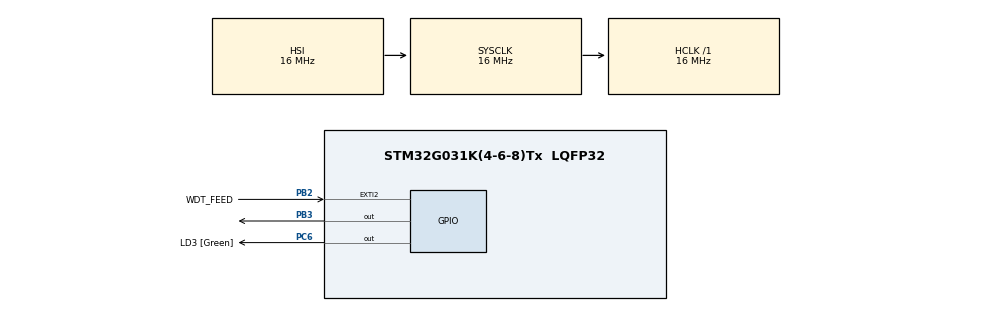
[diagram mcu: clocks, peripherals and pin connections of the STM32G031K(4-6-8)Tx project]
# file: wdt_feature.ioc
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Mcu.Family=STM32G0
Mcu.Name=STM32G031K(4-6-8)Tx
Mcu.Package=LQFP32
NVIC.EXTI2_3_IRQn=true\:0\:0\:false\:false\:true\:true\:true\:true
PA13.GPIO_Label=T_JTMS
PA13.Mode=Serial_Wire
PA13.Signal=SYS_SWDIO
PA14-BOOT0.GPIO_Label=T_JTCK
PA14-BOOT0.Mode=Serial_Wire
PA14-BOOT0.Signal=SYS_SWCLK
PA2.GPIO_Label=T_VCP_TX
PA2.GPIO_PuPd=GPIO_PULLUP
PA2.Signal=USART2_TX
PA3.GPIO_Label=T_VCP_RX
PA3.GPIO_PuPd=GPIO_PULLUP
PA3.Signal=USART2_RX
PB2.GPIO_Label=WDT_FEED
PB2.Signal=GPXTI2
PB3.Signal=GPIO_Output
PC14-OSC32_IN\ (PC14).Mode=LSE-External-Oscillator
PC14-OSC32_IN\ (PC14).Signal=RCC_OSC32_IN
PC15-OSC32_OUT\ (PC15).Mode=LSE-External-Oscillator
PC15-OSC32_OUT\ (PC15).Signal=RCC_OSC32_OUT
PC6.GPIO_Label=LD3 [Green]
PC6.Signal=GPIO_Output
ProjectManager.HeapSize=0x200
ProjectManager.StackSize=0x400
ProjectManager.TargetToolchain=STM32CubeIDE
RCC.AHBFreq_Value=16000000
RCC.CortexFreq_Value=16000000
RCC.EXTERNAL_CLOCK_VALUE=12288000
RCC.HCLKFreq_Value=16000000
RCC.HSE_VALUE=8000000
RCC.HSI_VALUE=16000000
RCC.SYSCLKFreq_VALUE=16000000
RCC.VCOOutputFreq_Value=128000000
board=NUCLEO-G031K8

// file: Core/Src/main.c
/* USER CODE BEGIN Header */
/**
  ******************************************************************************
  * @file           : main.c
  * @brief          : Main program body
  ******************************************************************************
  * @attention
  *
  * Copyright (c) 2022 STMicroelectronics.
  * All rights reserved.
  *
  * This software is licensed under terms that can be found in the LICENSE file
  * in the root directory of this software component.
  * If no LICENSE file comes with this software, it is provided AS-IS.
  *
  ******************************************************************************
  */
/* USER CODE END Header */
#include "main.h"

/* USER CODE BEGIN PV */
uint8_t flag = 0;
/* USER CODE END PV */

void SystemClock_Config(void);
static void MX_GPIO_Init(void);
/* USER CODE BEGIN PFP */
void HAL_GPIO_EXTI_Rising_Callback(uint16_t GPIO_Pin);
/* USER CODE END PFP */

int main(void)
{

  /* MCU Configuration--------------------------------------------------------*/

  /* Reset of all peripherals, Initializes the Flash interface and the Systick. */
  HAL_Init();

  /* Configure the system clock */
  SystemClock_Config();

  /* Initialize all configured peripherals */
  MX_GPIO_Init();

  /* Infinite loop */
  /* USER CODE BEGIN WHILE */
  while (1)
  {
	  if (flag == 0){
		  HAL_GPIO_WritePin(LD3_GPIO_Port, LD3_Pin, GPIO_PIN_SET);
		  HAL_GPIO_WritePin(GPIOB, GPIO_PIN_3, GPIO_PIN_SET);
		  HAL_Delay(500);
	  }
	  else if (flag == 1){
		  HAL_GPIO_WritePin(LD3_GPIO_Port, LD3_Pin, GPIO_PIN_RESET);
		  HAL_GPIO_WritePin(GPIOB, GPIO_PIN_3, GPIO_PIN_RESET);
	  }
	  /* USER CODE END WHILE */

  }
}

void SystemClock_Config(void)
{
  RCC_OscInitTypeDef RCC_OscInitStruct = {0};
  RCC_ClkInitTypeDef RCC_ClkInitStruct = {0};

  /** Configure the main internal regulator output voltage
  */
  HAL_PWREx_ControlVoltageScaling(PWR_REGULATOR_VOLTAGE_SCALE1);

  /** Initializes the RCC Oscillators according to the specified parameters
  * in the RCC_OscInitTypeDef structure.
  */
  RCC_OscInitStruct.OscillatorType = RCC_OSCILLATORTYPE_HSI;
  RCC_OscInitStruct.HSIState = RCC_HSI_ON;
  RCC_OscInitStruct.HSIDiv = RCC_HSI_DIV1;
  RCC_OscInitStruct.HSICalibrationValue = RCC_HSICALIBRATION_DEFAULT;
  RCC_OscInitStruct.PLL.PLLState = RCC_PLL_NONE;
  if (HAL_RCC_OscConfig(&RCC_OscInitStruct) != HAL_OK)
  {
    Error_Handler();
  }

  /** Initializes the CPU, AHB and APB buses clocks
  */
  RCC_ClkInitStruct.ClockType = RCC_CLOCKTYPE_HCLK|RCC_CLOCKTYPE_SYSCLK
                              |RCC_CLOCKTYPE_PCLK1;
  RCC_ClkInitStruct.SYSCLKSource = RCC_SYSCLKSOURCE_HSI;
  RCC_ClkInitStruct.AHBCLKDivider = RCC_SYSCLK_DIV1;
  RCC_ClkInitStruct.APB1CLKDivider = RCC_HCLK_DIV1;

  if (HAL_RCC_ClockConfig(&RCC_ClkInitStruct, FLASH_LATENCY_0) != HAL_OK)
  {
    Error_Handler();
  }
}

static void MX_GPIO_Init(void)
{
  GPIO_InitTypeDef GPIO_InitStruct = {0};

  /* GPIO Ports Clock Enable */
  __HAL_RCC_GPIOC_CLK_ENABLE();
  __HAL_RCC_GPIOA_CLK_ENABLE();
  __HAL_RCC_GPIOB_CLK_ENABLE();

  /*Configure GPIO pin Output Level */
  HAL_GPIO_WritePin(LD3_GPIO_Port, LD3_Pin, GPIO_PIN_RESET);

  /*Configure GPIO pin Output Level */
  HAL_GPIO_WritePin(GPIOB, GPIO_PIN_3, GPIO_PIN_RESET);

  /*Configure GPIO pins : T_VCP_TX_Pin T_VCP_RX_Pin */
  GPIO_InitStruct.Pin = T_VCP_TX_Pin|T_VCP_RX_Pin;
  GPIO_InitStruct.Mode = GPIO_MODE_AF_PP;
  GPIO_InitStruct.Pull = GPIO_PULLUP;
  GPIO_InitStruct.Speed = GPIO_SPEED_FREQ_LOW;
  GPIO_InitStruct.Alternate = GPIO_AF1_USART2;
  HAL_GPIO_Init(GPIOA, &GPIO_InitStruct);

  /*Configure GPIO pin : WDT_FEED_Pin */
  GPIO_InitStruct.Pin = WDT_FEED_Pin;
  GPIO_InitStruct.Mode = GPIO_MODE_IT_RISING;
  GPIO_InitStruct.Pull = GPIO_NOPULL;
  HAL_GPIO_Init(WDT_FEED_GPIO_Port, &GPIO_InitStruct);

  /*Configure GPIO pin : LD3_Pin */
  GPIO_InitStruct.Pin = LD3_Pin;
  GPIO_InitStruct.Mode = GPIO_MODE_OUTPUT_PP;
  GPIO_InitStruct.Pull = GPIO_NOPULL;
  GPIO_InitStruct.Speed = GPIO_SPEED_FREQ_LOW;
  HAL_GPIO_Init(LD3_GPIO_Port, &GPIO_InitStruct);

  /*Configure GPIO pin : PB3 */
  GPIO_InitStruct.Pin = GPIO_PIN_3;
  GPIO_InitStruct.Mode = GPIO_MODE_OUTPUT_PP;
  GPIO_InitStruct.Pull = GPIO_NOPULL;
  GPIO_InitStruct.Speed = GPIO_SPEED_FREQ_LOW;
  HAL_GPIO_Init(GPIOB, &GPIO_InitStruct);

  /* EXTI interrupt init*/
  HAL_NVIC_SetPriority(EXTI2_3_IRQn, 0, 0);
  HAL_NVIC_EnableIRQ(EXTI2_3_IRQn);

}

/* USER CODE BEGIN 4 */
void HAL_GPIO_EXTI_Rising_Callback(uint16_t GPIO_Pin)
{
  /* Prevent unused argument(s) compilation warning */
  UNUSED(GPIO_Pin);
  if (GPIO_Pin == WDT_FEED_Pin)
  {
	  flag++;
	  if (flag > 1 )
	  {
		  flag = 0;
	  }

  }

  /* NOTE: This function should not be modified, when the callback is needed,
           the HAL_GPIO_EXTI_Rising_Callback could be implemented in the user file
   */
}
/* USER CODE END 4 */

void Error_Handler(void)
{
  __disable_irq();
  while (1)
  {
  }
}
